# LPC111x/LPC11Cxx/LPC11xxL/LPC11xxXL register map
File version: 6
CPU: CM0 r0p0, little endian, no MPU, no FPU, 2 interrupt priority bits
Registers are 32-bit, read-write, reset 0x0 unless marked. A register's access mark holds for its fields unless they carry their own. Offsets are from the block's base; lines under a group give offsets from that group; [hi:lo] are bit positions; {n}, {i} and the like mark numbered series; 'fields as' and 'values as' point back to an identical list; <NAME> marks a mode.

## Memory map
0x40000000 I2C size 0xFFF — Inter-Integrated Circuit (I²C) Controller
0x40004000 WWDT size 0xFFF — Windowed Watchdog Timer
0x40008000 UART size 0xFFF — Universal Asynchronous Receiver/Transmitter
0x4000C000 CT16B0 size 0xFFF — 16-bit Counter/Timer
0x40010000 CT16B1 size 0xFFF
0x40014000 CT32B0 size 0xFFF — 32-bit Counter/Timer
0x40018000 CT32B1 size 0xFFF
0x4001C000 ADC size 0xFFF — 10-bit Analog-to-Digital Converter
0x40038000 PMU size 0xFFF — Power Management Unit
0x4003C000 FLASHCTRL size 0xFFF — Flash Programming Firmware
0x40040000 SPI0 size 0xFFF — Serial Peripheral Interface
0x40044000 IOCON size 0xFFF — I/O Configuration Block
0x40048000 SYSCON size 0xFFF — System Configuration Block
0x40050000 C_CAN size 0xFFF — Controller Area Network Controller
0x40058000 SPI1 size 0xFFF
0x50000000 GPIO0 size 0xFFFFFF — General Purpose I/O
0x50010000 GPIO1 size 0xFFFFFF
0x50020000 GPIO2 size 0xFFFFFF
0x50030000 GPIO3 size 0xFFFFFF

## Interrupts
{n} PIO0_{n} (SYSCON) (n=0..11)
12 PIO1_0 (SYSCON)
13 C_CAN
14 SPI1
15 I2C
16 CT16B0
17 CT16B1
18 CT32B0
19 CT32B1
20 SPI0
21 UART
24 ADC
25 WDT (WWDT)
26 BOD (SYSCON)
27 FMC (FLASHCTRL)
28 GPIO3
29 GPIO2
30 GPIO1
31 GPIO0

## WWDT — Windowed Watchdog Timer
Base 0x40004000
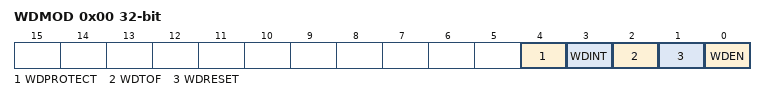
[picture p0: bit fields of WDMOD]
0x00 WDMOD — Watchdog mode register. This register contains the basic mode and status of the Watchdog Timer
  [4] WDPROTECT — Watchdog update mode. This bit is Set Only.
    0=ANYTIME (The watchdog reload value (WDTC) can be changed at any time); 1=LOWCOUNTER (The watchdog reload value (WDTC) can be changed only after the counter is below the value of WDWARNINT and WDWINDOW. Note: this mode is intended for use only when WDRESET =1)
  [3] WDINT — Watchdog interrupt flag. Set when the timer reaches the value in WDWARNINT. Cleared by software.
  [2] WDTOF — Watchdog time-out flag. Set when the watchdog timer times out, by a feed error, or by events associated with WDPROTECT, cleared by software. Causes a chip reset if WDRESET = 1.
  [1] WDRESET — Watchdog reset enable bit. This bit is Set Only.
    0=NORESET (A watchdog timeout will not cause a chip reset); 1=RESET (A watchdog timeout will cause a chip reset)
  [0] WDEN — Watchdog enable bit. This bit is Set Only. Setting this bit to one also locks the watchdog clock source. Once the watchdog timer is enabled, the watchdog timer clock source cannot be changed. If the watchdog timer is needed in Deep-sleep mode, the watchdog clock source must be changed to the watchdog oscillator before setting this bit to one.
    0=STOPPED (The watchdog timer is stopped); 1=RUN (The watchdog timer is running)
0x04 WDTC reset 0xFF — Watchdog timer constant register. This register determines the time-out value
  [23:0] Count — Watchdog time-out interval.
0x08 WDFEED wo reset not defined — Watchdog feed sequence register. Writing 0xAA followed by 0x55 to this register reloads the Watchdog timer with the value contained in WDTC
  [7:0] Feed — Feed value should be 0xAA followed by 0x55.
0x0C WDTV ro reset 0xFF — Watchdog timer value register. This register reads out the current value of the Watchdog timer
  [23:0] Count — Counter timer value.
0x14 WDWARNINT — Watchdog Warning Interrupt compare value
  [9:0] WARNINT — Watchdog warning interrupt compare value.
0x18 WDWINDOW reset 0xFFFFFF — Watchdog Window compare value
  [23:0] WINDOW — Watchdog window value.

## PMU — Power Management Unit
Base 0x40038000
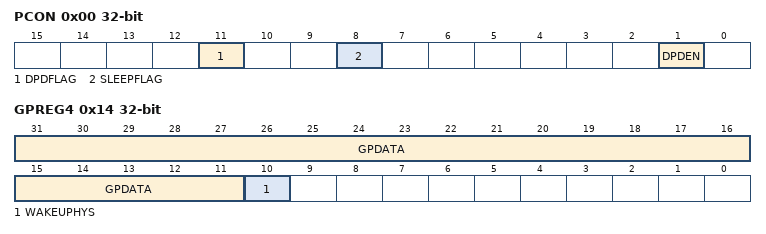
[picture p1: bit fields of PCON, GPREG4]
0x00 PCON — Power control register
  [11] DPDFLAG — Deep power-down flag.
    0=NODEEPPOWERDOWN (Read: Deep power-down mode not entered. Write: No effect); 1=DEEPPOWERDOWN (Read: Deep power-down mode entered. Write: Clear the Deep power-down flag)
  [8] SLEEPFLAG — Sleep mode flag.
    0=NOPOWERDOWN (Read: No power-down mode entered. LPC111x/LPC11C1x is in Active mode. Write: No effect); 1=POWERDOWN (Read: Sleep/Deep-sleep or Deep power-down mode entered. Write: Writing a 1 clears the SLEEPFLAG bit to 0)
  [1] DPDEN — Deep power-down mode enable.
    0=SLEEPMODE (ARM WFI will enter Sleep or Deep-sleep mode (clock to ARM Cortex-M0 core turned off)); 1=DEEPPOWERDOWN (ARM WFI will enter Deep-power down mode (ARM Cortex-M0 core powered-down))
{0x4+4i} GPREG{i} (i=0..3) — General purpose register
  [31:0] GPDATA — Data retained during Deep power-down mode.
0x14 GPREG4 — General purpose register 4
  [31:11] GPDATA — Data retained during Deep power-down mode.
  [10] WAKEUPHYS — WAKEUP pin hysteresis enable.
    1=ENABLED (Hysteresis for WAKEUP pin enabled); 0=DISABLED (Hysteresis for WAKUP pin disabled)
